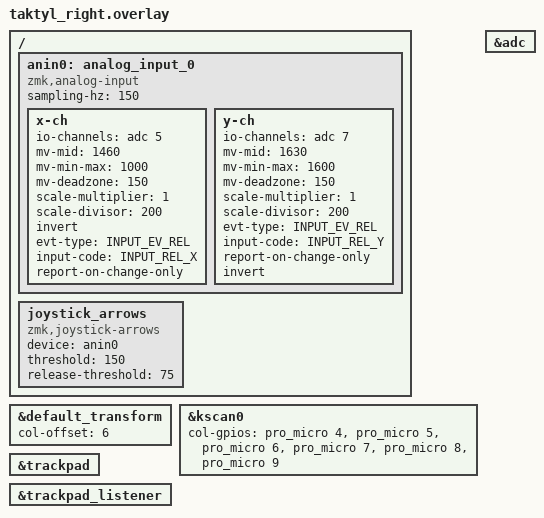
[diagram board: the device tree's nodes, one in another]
#include "taktyl.dtsi"

&default_transform { // Offset of 3 because the left side has 3 columns
    col-offset = <6>;
};
&kscan0 {
    col-gpios = <&pro_micro 4 GPIO_ACTIVE_HIGH>,
                <&pro_micro 5 GPIO_ACTIVE_HIGH>,
                <&pro_micro 6 GPIO_ACTIVE_HIGH>,
                <&pro_micro 7 GPIO_ACTIVE_HIGH>,
                <&pro_micro 8 GPIO_ACTIVE_HIGH>,
                <&pro_micro 9 GPIO_ACTIVE_HIGH>;
};

/ {
	anin0: analog_input_0 {
		compatible = "zmk,analog-input";
		sampling-hz = <150>;
		/* Canaux echanges : l'ancien driver lisait AIN5 pour x-ch et AIN7 pour
		 * y-ch (ordre du tampon ADC). Les reglages ci-dessous restent donc
		 * appliques au meme signal qu'avant. */
		x-ch {
			io-channels = <&adc 5>; // <--- see ain-map.png for nRF52840
			mv-mid = <1460>;
			mv-min-max = <1000>;
			/* 400 etait tronque a 144 par l'ancien driver : 150 garde le meme ressenti */
			mv-deadzone = <150>;
			scale-multiplier = <1>;
			scale-divisor = <200>;
            invert;
			evt-type = <INPUT_EV_REL>;
			input-code = <INPUT_REL_X>;
			report-on-change-only;
		
		};
		y-ch {
			io-channels = <&adc 7>; // <--- see ain-map.png for nRF52840
			mv-mid = <1630>;
			mv-min-max = <1600>;
			mv-deadzone = <150>;
			scale-multiplier = <1>;
			scale-divisor = <200>;
			evt-type = <INPUT_EV_REL>;
			input-code = <INPUT_REL_Y>;
			report-on-change-only;
			invert;
		};
	};
};

&adc {
	status = "okay";
};

/* Le joystick ne pilote plus la souris : il envoie les fleches. */
/ {
    joystick_arrows {
        compatible = "zmk,joystick-arrows";
        device = <&anin0>;
        threshold = <150>;          /* mV au-dela de la zone morte */
        release-threshold = <75>;
    };
};

&trackpad {
	status = "okay";
};

&trackpad_listener {
	status = "okay";	
};  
